# AVR16EB28 register map
Vendor: Atmel; File version: 1.0
CPU: other r0p0, little endian, no MPU, no FPU, 4 interrupt priority bits
Registers are 8-bit, read-write, reset 0x0 unless marked. A register's access mark holds for its fields unless they carry their own. Offsets are from the block's base; [hi:lo] are bit positions; {n}, {i} and the like mark numbered series; 'fields as' and 'values as' point back to an identical list.

## WEX0 — Waveform Extension
Base 0x00800C80
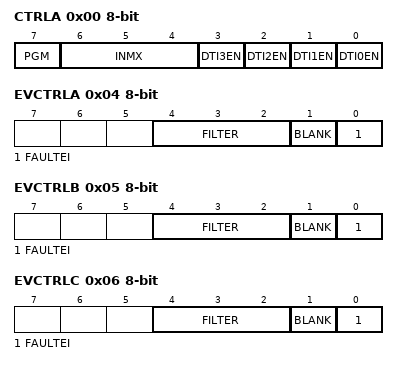
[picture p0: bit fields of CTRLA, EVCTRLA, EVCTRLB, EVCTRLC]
0x00 CTRLA — Control A
  [7] PGM — Pattern Generation Mode
  [6:4] INMX — Input Matrix
    0=DIRECT (Direct from TCE0); 2=CWCMA (Common Waveform Channel Mode A. Single WO); 3=CWCMB (Common Waveform Channel Mode B. WO from two PWM channels)
  [n] DTI{n}EN (n=0..3) — Dead-Time Insertion CMP{n} Enable
0x01 CTRLB — Control B
  [1:0] UPDSRC — Update Source
    0=TCPWM0 (Timer/Counter for PWM 0 update condition); 3=SW (Software update only. No hardware update condition)
0x02 CTRLC — Control C
  [2:0] CMD — Command
    0=NONE (No Command); 1=UPDATE (Force update of Dead-time, SWAP and PGM buffer registers.); 2=FAULTSET (Set Fault Detection); 3=FAULTCLR (Clear Fault Detection); 4=BLANKSET (Set SW Blanking); 5=BLANKCLR (Clear SW Blanking)
0x04 EVCTRLA — Event Control A
  [4:2] FILTER — Fault Event Filter Enable
    0=ZERO (No digital filter); 1=SAMPLE1 (One Sample); 2=SAMPLE2 (Two Samples); 3=SAMPLE3 (Three Samples); 4=SAMPLE4 (Four Samples); 5=SAMPLE5 (Five Samples); 6=SAMPLE6 (Six Samples); 7=SAMPLE7 (Seven Samples)
  [1] BLANK — Fault Event Blanking Enable
  [0] FAULTEI — Fault Event Input Enable
0x05 EVCTRLB — Event Control B
  fields as EVCTRLA
0x06 EVCTRLC — Event Control C
  fields as EVCTRLA
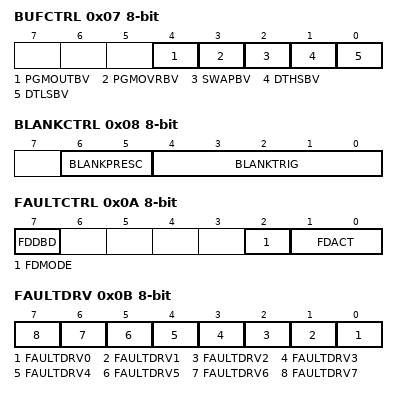
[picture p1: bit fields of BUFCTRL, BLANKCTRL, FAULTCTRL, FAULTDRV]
0x07 BUFCTRL — Buffer Valid Control
  [4] PGMOUTBV — PGM Output Value Buffer Valid
  [3] PGMOVRBV — PGM Override Buffer Valid
  [2] SWAPBV — Swap Buffer Valid
  [1] DTHSBV — Dead-time High Side Buffer Valid
  [0] DTLSBV — Dead-time Low Side Buffer Valid
0x08 BLANKCTRL — Blanking Control
  [6:5] BLANKPRESC — Blanking Prescaler
    0=DIV1 (No prescaling); 1=DIV4 (Divide CLK_PER by 4); 2=DIV16 (Divide CLK_PER by 16); 3=DIV64 (Divide CLK_PER by 64)
  [4:0] BLANKTRIG — Blanking Trigger
    0=NONE (No HW trigger (Software only)); 4=TCE0UPD (TCE0 Update Condition); 8=TCE0CMP0 (TCE0 Compare 0); 12=TCE0CMP1 (TCE0 Compare 1); 16=TCE0CMP2 (TCE0 Compare 2); 20=TCE0CMP3 (TCE0 Compare 3)
0x09 BLANKTIME — Blanking Time
0x0A FAULTCTRL — Fault Control
  [7] FDDBD — Fault Detection on Debug Break Detection
    0=FAULT (OCD Break request is treated as a fault if fault protection is enabled); 1=IGNORE (OCD Breask request will not trigger a fault)
  [2] FDMODE — Fault Detection Restart Mode
    0=LATCHED (Latched Mode. Output will remain in fault state until fault condition is no longer active and FDF is cleared by SW.); 1=CBC (Cycle-by-cycle mode. Waveform output will remain in fault state until fault condition is no longer active.)
  [1:0] FDACT — Fault Detection Action
    0=NONE (None. Fault Protection Disabled); 1=LOW (Drive all pins low); 3=CUSTOM (Drive all pins to setting defined by FAULTDRV and FAULTVAL)
0x0B FAULTDRV — Fault Drive
  [n] FAULTDRV{n} (n=0..7) — Fault Drive Enable Bit {n}
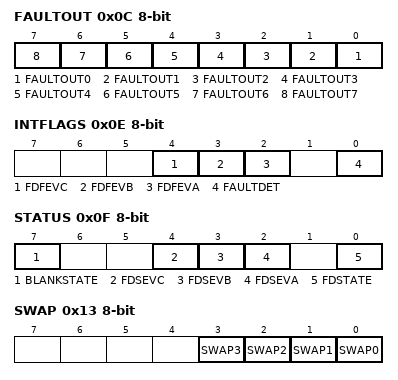
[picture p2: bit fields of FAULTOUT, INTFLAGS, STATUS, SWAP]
0x0C FAULTOUT — Fault Output
  [n] FAULTOUT{n} (n=0..7) — Fault Output Value Bit {n}
0x0D INTCTRL — Interrupt Control
  [0] FAULTDET — Fault Detection Interrupt Enable
0x0E INTFLAGS — Interrupt Flags
  [4] FDFEVC — Fault Detection Flag Event Input C
  [3] FDFEVB — Fault Detection Flag Event Input B
  [2] FDFEVA — Fault Detection Flag Event Input A
  [0] FAULTDET — Fault Detection Interrupt Flag
0x0F STATUS ro
  [7] BLANKSTATE — Blanking State
    0=OFF (Blanking off); 1=ON (Blanking active)
  [4] FDSEVC — Fault Detection State Event C
  [3] FDSEVB — Fault Detection State Event B
  [2] FDSEVA — Fault Detection State Event A
  [0] FDSTATE — Fault Detection State
    0=NORMAL (Normal state); 1=FAULT (Fault state)
0x10 DTLS — Dead-time Low Side
0x11 DTHS — Dead-time High Side
0x12 DTBOTH — Dead-time Both Sides
0x13 SWAP — DTI Swap
  [n] SWAP{n} (n=0..3) — Swap DTI Output Pair {n}
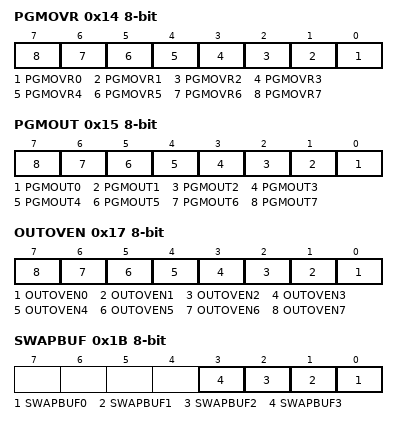
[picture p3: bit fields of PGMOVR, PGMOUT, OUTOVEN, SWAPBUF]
0x14 PGMOVR — Pattern Generation Override
  [n] PGMOVR{n} (n=0..7) — Pattern Generation Override Enable Bit {n}
0x15 PGMOUT — Pattern Generation Output
  [n] PGMOUT{n} (n=0..7) — Pattern Generation Output Value Bit {n}
0x17 OUTOVEN — Output Override Enable
  [n] OUTOVEN{n} (n=0..7) — Output Override Enable Bit {n}
0x18 DTLSBUF — Dead-time Low Side Buffer
0x19 DTHSBUF — Dead-time High Side Buffer
0x1A DTBOTHBUF — Dead-time Both Sides Buffer
0x1B SWAPBUF — DTI Swap Buffer
  [n] SWAPBUF{n} (n=0..3) — Swap DTI Output Pair {n} Buffer
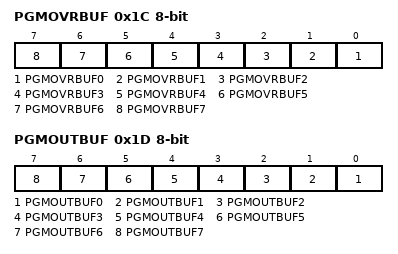
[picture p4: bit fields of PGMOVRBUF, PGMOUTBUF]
0x1C PGMOVRBUF — Pattern Generation Override Buffer
  [n] PGMOVRBUF{n} (n=0..7) — Pattern Generation Override Enable Buffer Bit {n}
0x1D PGMOUTBUF — Pattern Generation Output Buffer
  [n] PGMOUTBUF{n} (n=0..7) — Pattern Generation Output Value Buffer Bit {n}
